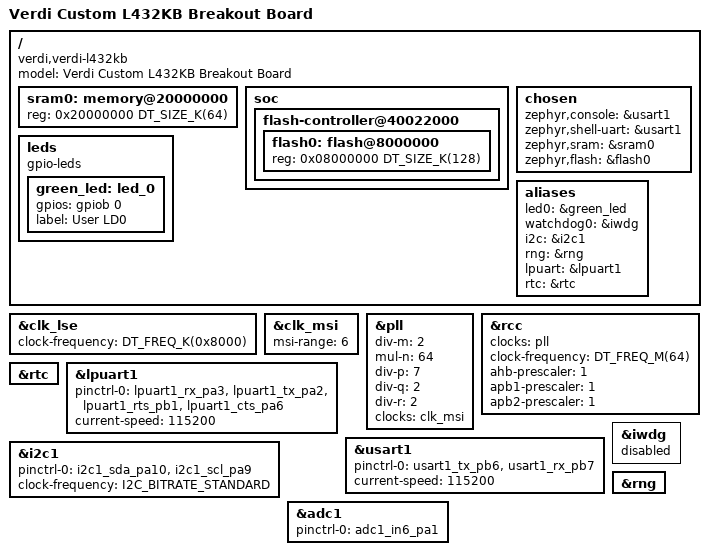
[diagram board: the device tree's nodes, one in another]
/dts-v1/;
#include <st/l4/stm32l432Xc.dtsi>
#include <st/l4/stm32l432k(b-c)ux-pinctrl.dtsi>

/ {
	model = "Verdi Custom L432KB Breakout Board";
	compatible = "verdi,verdi-l432kb";
	
	sram0: memory@20000000 {
		reg = <0x20000000 DT_SIZE_K(64)>;
	};

	soc {
		flash-controller@40022000 {
			flash0: flash@8000000 {
				reg = <0x08000000 DT_SIZE_K(128)>;
			};
		};
	};

	chosen {
		zephyr,console = &usart1;
		zephyr,shell-uart = &usart1;
		zephyr,sram = &sram0;
		zephyr,flash = &flash0;
	};

	leds {
		compatible = "gpio-leds";
		green_led: led_0 {
			gpios = <&gpiob 0 GPIO_ACTIVE_HIGH>;
			label = "User LD0";
		};
	};

	aliases {
		led0 = &green_led;
		watchdog0 = &iwdg;
		i2c = &i2c1;
		rng = &rng;
		lpuart = &lpuart1;
		rtc = &rtc;
	};


};

// Clock Configurations

&clk_lse {
	status = "okay";
	clock-frequency = <DT_FREQ_K(0x8000)>;
};

&clk_msi {
	msi-range = <6>; /* Enum 6 for 4MHz */
	status = "okay";
};

&pll {
	div-m = <2>;  /* PLLM */
	mul-n = <64>; /* PLLN */
	div-p = <7>; /* Irrelevant (SAI) */
	div-q = <2>; /* Irrelenvat (4M1) */
	div-r = <2>; /* PLLClock */
	clocks = <&clk_msi>; /* 4 MHz in */
	status = "okay";
};

&rcc {
	clocks = <&pll>;
	clock-frequency = <DT_FREQ_M(64)>;
	ahb-prescaler = <1>;
	apb1-prescaler = <1>;
	apb2-prescaler = <1>;
};



// RTC
&rtc {
	status = "okay";
};

// LPUART1
&lpuart1 {
	pinctrl-0 = <&lpuart1_rx_pa3 &lpuart1_tx_pa2 &lpuart1_rts_pb1 &lpuart1_cts_pa6>;
	current-speed = <115200>;
	status = "okay";
};

// UART1
&usart1 {
	pinctrl-0 = <&usart1_tx_pb6 &usart1_rx_pb7>;
	current-speed = <115200>;
	status = "okay";
};



// Internal Watchdog --> disable for debugging
&iwdg {
	status = "disabled";
};

//I2C
&i2c1 {
	pinctrl-0 = <&i2c1_sda_pa10 &i2c1_scl_pa9>;
	clock-frequency = <I2C_BITRATE_STANDARD>;
	status = "okay";
};

//ADC
&adc1 {
	pinctrl-0 = <&adc1_in6_pa1>;
	status = "okay";
};

//RNG
&rng {
	status = "okay";
};

